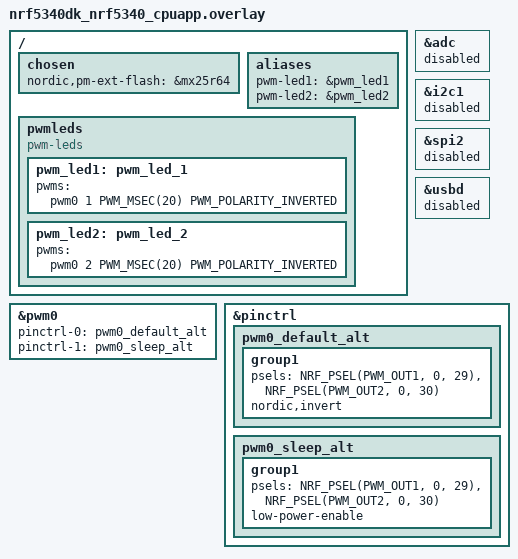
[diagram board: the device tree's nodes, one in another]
/*
 * SPDX-FileCopyrightText: 2022 Project CHIP Authors
 *
 * SPDX-License-Identifier: Apache-2.0
 */

/ {
	chosen {
		nordic,pm-ext-flash = &mx25r64;
	};

	/*
	* Configure LED2 and LED3 to show the state of the
	* window cover,by using the LED's brightness level.
	*/
	aliases {
		pwm-led1 = &pwm_led1;
		pwm-led2 = &pwm_led2;
	};

	pwmleds {
		compatible = "pwm-leds";
		pwm_led1: pwm_led_1 {
			pwms = <&pwm0 1 PWM_MSEC(20) PWM_POLARITY_INVERTED>;
		};
		pwm_led2: pwm_led_2 {
			pwms = <&pwm0 2 PWM_MSEC(20) PWM_POLARITY_INVERTED>;
		};
	};
};

/* Disable unused peripherals to reduce power consumption */
&adc {
	status = "disabled";
};
&i2c1 {
	status = "disabled";
};
&spi2 {
	status = "disabled";
};
&usbd {
	status = "disabled";
};

&pwm0 {
	pinctrl-0 = <&pwm0_default_alt>;
	pinctrl-1 = <&pwm0_sleep_alt>;
	pinctrl-names = "default", "sleep";
};

&pinctrl {
	pwm0_default_alt: pwm0_default_alt {
		group1 {
			psels = <NRF_PSEL(PWM_OUT1, 0, 29)>, <NRF_PSEL(PWM_OUT2, 0, 30)>;
			nordic,invert;
		};
	};

	pwm0_sleep_alt: pwm0_sleep_alt {
		group1 {
			psels = <NRF_PSEL(PWM_OUT1, 0, 29)>, <NRF_PSEL(PWM_OUT2, 0, 30)>;
			low-power-enable;
		};
	};
};
